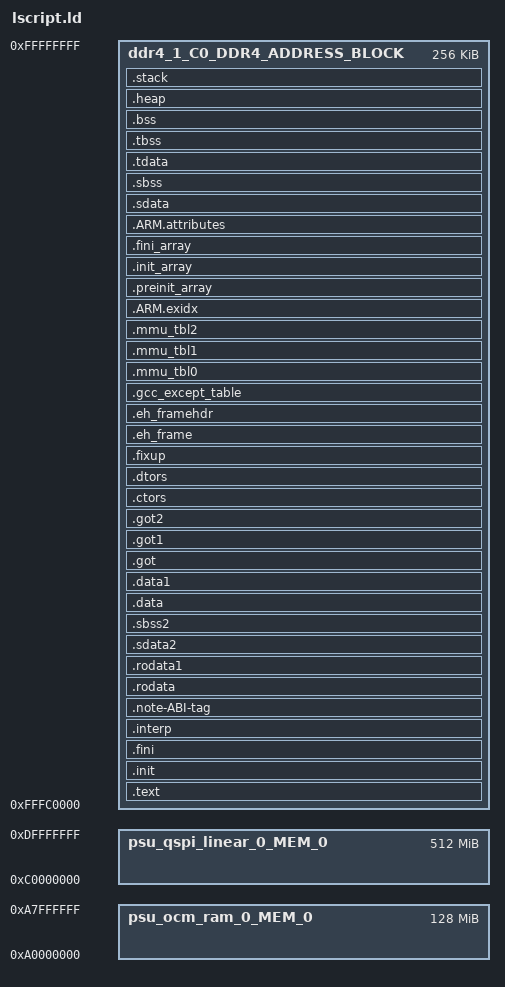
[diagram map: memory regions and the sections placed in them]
/*******************************************************************/
/*                                                                 */
/* This file is automatically generated by linker script generator.*/
/*                                                                 */
/* Version: 2018.3.1                                               */
/*                                                                 */
/* Copyright (c) 2010-2016 Xilinx, Inc.  All rights reserved.      */
/*                                                                 */
/* Description : ARM v8 Linker Script                           */
/*                                                                 */
/*******************************************************************/

_STACK_SIZE = DEFINED(_STACK_SIZE) ? _STACK_SIZE : 0x2000;
_HEAP_SIZE = DEFINED(_HEAP_SIZE) ? _HEAP_SIZE : 0x2000;

_EL0_STACK_SIZE = DEFINED(_EL0_STACK_SIZE) ? _EL0_STACK_SIZE : 1024;
_EL1_STACK_SIZE = DEFINED(_EL1_STACK_SIZE) ? _EL1_STACK_SIZE : 2048;
_EL2_STACK_SIZE = DEFINED(_EL2_STACK_SIZE) ? _EL2_STACK_SIZE : 1024;

/* Define Memories in the system */

MEMORY
{
   psu_ocm_ram_0_MEM_0 : ORIGIN = 0xA0000000, LENGTH = 0x8000000
   ddr4_1_C0_DDR4_ADDRESS_BLOCK : ORIGIN = 0xFFFC0000, LENGTH = 0x40000
   psu_qspi_linear_0_MEM_0 : ORIGIN = 0xC0000000, LENGTH = 0x20000000
}

/* Specify the default entry point to the program */

ENTRY(_vector_table)

/* Define the sections, and where they are mapped in memory */

SECTIONS
{
.text : {
   KEEP (*(.vectors))
   *(.boot)
   *(.text)
   *(.text.*)
   *(.gnu.linkonce.t.*)
   *(.plt)
   *(.gnu_warning)
   *(.gcc_execpt_table)
   *(.glue_7)
   *(.glue_7t)
   *(.ARM.extab)
   *(.gnu.linkonce.armextab.*)
} > ddr4_1_C0_DDR4_ADDRESS_BLOCK

.init (ALIGN(64)) : {
   KEEP (*(.init))
} > ddr4_1_C0_DDR4_ADDRESS_BLOCK

.fini (ALIGN(64)) : {
   KEEP (*(.fini))
} > ddr4_1_C0_DDR4_ADDRESS_BLOCK

.interp : {
   KEEP (*(.interp))
} > ddr4_1_C0_DDR4_ADDRESS_BLOCK

.note-ABI-tag : {
   KEEP (*(.note-ABI-tag))
} > ddr4_1_C0_DDR4_ADDRESS_BLOCK

.rodata : {
   . = ALIGN(64);
   __rodata_start = .;
   *(.rodata)
   *(.rodata.*)
   *(.gnu.linkonce.r.*)
   __rodata_end = .;
} > ddr4_1_C0_DDR4_ADDRESS_BLOCK

.rodata1 : {
   . = ALIGN(64);
   __rodata1_start = .;
   *(.rodata1)
   *(.rodata1.*)
   __rodata1_end = .;
} > ddr4_1_C0_DDR4_ADDRESS_BLOCK

.sdata2 : {
   . = ALIGN(64);
   __sdata2_start = .;
   *(.sdata2)
   *(.sdata2.*)
   *(.gnu.linkonce.s2.*)
   __sdata2_end = .;
} > ddr4_1_C0_DDR4_ADDRESS_BLOCK

.sbss2 : {
   . = ALIGN(64);
   __sbss2_start = .;
   *(.sbss2)
   *(.sbss2.*)
   *(.gnu.linkonce.sb2.*)
   __sbss2_end = .;
} > ddr4_1_C0_DDR4_ADDRESS_BLOCK

.data : {
   . = ALIGN(64);
   __data_start = .;
   *(.data)
   *(.data.*)
   *(.gnu.linkonce.d.*)
   *(.jcr)
   *(.got)
   *(.got.plt)
   __data_end = .;
} > ddr4_1_C0_DDR4_ADDRESS_BLOCK

.data1 : {
   . = ALIGN(64);
   __data1_start = .;
   *(.data1)
   *(.data1.*)
   __data1_end = .;
} > ddr4_1_C0_DDR4_ADDRESS_BLOCK

.got : {
   *(.got)
} > ddr4_1_C0_DDR4_ADDRESS_BLOCK

.got1 : {
   *(.got1)
} > ddr4_1_C0_DDR4_ADDRESS_BLOCK

.got2 : {
   *(.got2)
} > ddr4_1_C0_DDR4_ADDRESS_BLOCK

.ctors : {
   . = ALIGN(64);
   __CTOR_LIST__ = .;
   ___CTORS_LIST___ = .;
   KEEP (*crtbegin.o(.ctors))
   KEEP (*(EXCLUDE_FILE(*crtend.o) .ctors))
   KEEP (*(SORT(.ctors.*)))
   KEEP (*(.ctors))
   __CTOR_END__ = .;
   ___CTORS_END___ = .;
} > ddr4_1_C0_DDR4_ADDRESS_BLOCK

.dtors : {
   . = ALIGN(64);
   __DTOR_LIST__ = .;
   ___DTORS_LIST___ = .;
   KEEP (*crtbegin.o(.dtors))
   KEEP (*(EXCLUDE_FILE(*crtend.o) .dtors))
   KEEP (*(SORT(.dtors.*)))
   KEEP (*(.dtors))
   __DTOR_END__ = .;
   ___DTORS_END___ = .;
} > ddr4_1_C0_DDR4_ADDRESS_BLOCK

.fixup : {
   __fixup_start = .;
   *(.fixup)
   __fixup_end = .;
} > ddr4_1_C0_DDR4_ADDRESS_BLOCK

.eh_frame : {
   *(.eh_frame)
} > ddr4_1_C0_DDR4_ADDRESS_BLOCK

.eh_framehdr : {
   __eh_framehdr_start = .;
   *(.eh_framehdr)
   __eh_framehdr_end = .;
} > ddr4_1_C0_DDR4_ADDRESS_BLOCK

.gcc_except_table : {
   *(.gcc_except_table)
} > ddr4_1_C0_DDR4_ADDRESS_BLOCK

.mmu_tbl0 (ALIGN(4096)) : {
   __mmu_tbl0_start = .;
   *(.mmu_tbl0)
   __mmu_tbl0_end = .;
} > ddr4_1_C0_DDR4_ADDRESS_BLOCK

.mmu_tbl1 (ALIGN(4096)) : {
   __mmu_tbl1_start = .;
   *(.mmu_tbl1)
   __mmu_tbl1_end = .;
} > ddr4_1_C0_DDR4_ADDRESS_BLOCK

.mmu_tbl2 (ALIGN(4096)) : {
   __mmu_tbl2_start = .;
   *(.mmu_tbl2)
   __mmu_tbl2_end = .;
} > ddr4_1_C0_DDR4_ADDRESS_BLOCK

.ARM.exidx : {
   __exidx_start = .;
   *(.ARM.exidx*)
   *(.gnu.linkonce.armexidix.*.*)
   __exidx_end = .;
} > ddr4_1_C0_DDR4_ADDRESS_BLOCK

.preinit_array : {
   . = ALIGN(64);
   __preinit_array_start = .;
   KEEP (*(SORT(.preinit_array.*)))
   KEEP (*(.preinit_array))
   __preinit_array_end = .;
} > ddr4_1_C0_DDR4_ADDRESS_BLOCK

.init_array : {
   . = ALIGN(64);
   __init_array_start = .;
   KEEP (*(SORT(.init_array.*)))
   KEEP (*(.init_array))
   __init_array_end = .;
} > ddr4_1_C0_DDR4_ADDRESS_BLOCK

.fini_array : {
   . = ALIGN(64);
   __fini_array_start = .;
   KEEP (*(SORT(.fini_array.*)))
   KEEP (*(.fini_array))
   __fini_array_end = .;
} > ddr4_1_C0_DDR4_ADDRESS_BLOCK

.ARM.attributes : {
   __ARM.attributes_start = .;
   *(.ARM.attributes)
   __ARM.attributes_end = .;
} > ddr4_1_C0_DDR4_ADDRESS_BLOCK

.sdata : {
   . = ALIGN(64);
   __sdata_start = .;
   *(.sdata)
   *(.sdata.*)
   *(.gnu.linkonce.s.*)
   __sdata_end = .;
} > ddr4_1_C0_DDR4_ADDRESS_BLOCK

.sbss (NOLOAD) : {
   . = ALIGN(64);
   __sbss_start = .;
   *(.sbss)
   *(.sbss.*)
   *(.gnu.linkonce.sb.*)
   . = ALIGN(64);
   __sbss_end = .;
} > ddr4_1_C0_DDR4_ADDRESS_BLOCK

.tdata : {
   . = ALIGN(64);
   __tdata_start = .;
   *(.tdata)
   *(.tdata.*)
   *(.gnu.linkonce.td.*)
   __tdata_end = .;
} > ddr4_1_C0_DDR4_ADDRESS_BLOCK

.tbss : {
   . = ALIGN(64);
   __tbss_start = .;
   *(.tbss)
   *(.tbss.*)
   *(.gnu.linkonce.tb.*)
   __tbss_end = .;
} > ddr4_1_C0_DDR4_ADDRESS_BLOCK

.bss (NOLOAD) : {
   . = ALIGN(64);
   __bss_start__ = .;
   *(.bss)
   *(.bss.*)
   *(.gnu.linkonce.b.*)
   *(COMMON)
   . = ALIGN(64);
   __bss_end__ = .;
} > ddr4_1_C0_DDR4_ADDRESS_BLOCK

_SDA_BASE_ = __sdata_start + ((__sbss_end - __sdata_start) / 2 );

_SDA2_BASE_ = __sdata2_start + ((__sbss2_end - __sdata2_start) / 2 );

/* Generate Stack and Heap definitions */

.heap (NOLOAD) : {
   . = ALIGN(64);
   _heap = .;
   HeapBase = .;
   _heap_start = .;
   . += _HEAP_SIZE;
   _heap_end = .;
   HeapLimit = .;
} > ddr4_1_C0_DDR4_ADDRESS_BLOCK

.stack (NOLOAD) : {
   . = ALIGN(64);
   _el3_stack_end = .;
   . += _STACK_SIZE;
   __el3_stack = .;
   _el2_stack_end = .;
   . += _EL2_STACK_SIZE;
   . = ALIGN(64);
   __el2_stack = .;
   _el1_stack_end = .;
   . += _EL1_STACK_SIZE;
   . = ALIGN(64);
   __el1_stack = .;
   _el0_stack_end = .;
   . += _EL0_STACK_SIZE;
   . = ALIGN(64);
   __el0_stack = .;
} > ddr4_1_C0_DDR4_ADDRESS_BLOCK

_end = .;
}

